# DCAN_0_DATA register map
Vendor: Texas Instruments
Peripheral module from a debugger description file (folder 66AK2G0x_66AK2G1x).
Registers are 32-bit, read-only, reset 0x0 unless marked. A register's access mark holds for its fields unless they carry their own. Offsets are as the file gives them; lines under a group give offsets from that group; [hi:lo] are bit positions; {n}, {i} and the like mark numbered series; 'fields as' and 'values as' point back to an identical list; <NAME> marks a mode.

## DCAN_0_DATA
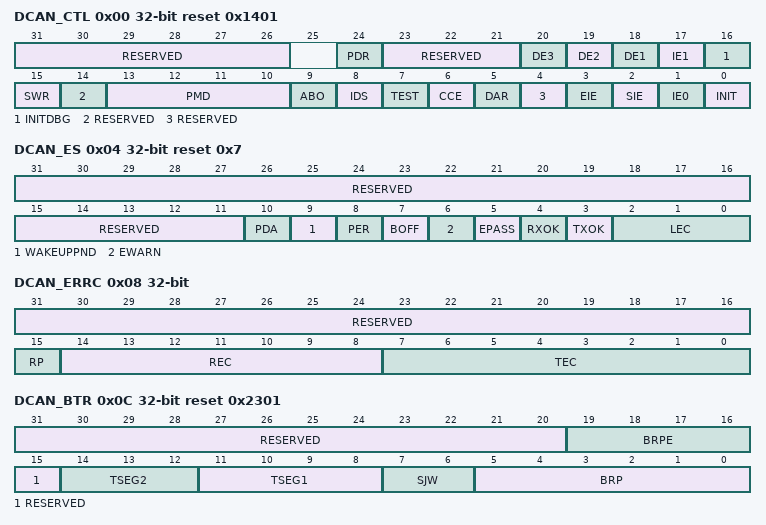
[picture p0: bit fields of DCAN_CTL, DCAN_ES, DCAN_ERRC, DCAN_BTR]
0x00 DCAN_CTL access per field reset 0x1401
  [31:26] RESERVED ro — These bits are always read as 0. Writes have no effect.
  [24] PDR rw — Request for local low power-down mode 0h (R/W) = No application request for local low power-down mode. If the application has cleared this bit while DCAN in local power-down mode, also the INIT bit has to be cleared. 1h (R/W) = Local power-down mode has been requested by application. The DCAN will acknowledge the local power-down mode by setting bit PDA in the
  [23:21] RESERVED ro — These bits are always read as 0. Writes have no effect.
  [20] DE3 rw — Enable DMA request line for IF3. Note: A pending DMA request for IF3 remains active until first access to one of the IF3 registers. 0h (R/W) = Disabled 1h (R/W) = Enabled
  [19] DE2 rw — Enable DMA request line for IF2. Note: A pending DMA request for IF2 remains active until first access to one of the IF2 registers. 0h (R/W) = Disabled 1h (R/W) = Enabled
  [18] DE1 rw — Enable DMA request line for IF1. Note: A pending DMA request for IF1 remains active until first access to one of the IF1 registers. 0h (R/W) = Disabled 1h (R/W) = Enabled
  [17] IE1 rw — Interrupt line 1 enable 0h (R/W) = Disabled - Module interrupt INT1 is always low. 1h (R/W) = Enabled - interrupts will assert line INT1 to one; line remains active until pending interrupts are processed.
  [16] INITDBG rw — Internal init state while debug access 0h (R/W) = Not in debug mode, or debug mode requested but not entered. 1h (R/W) = Debug mode requested and internally entered; the DCAN is ready for debug accesses.
  [15] SWR rw — Software reset enable. Note: To execute software reset, the following procedure is necessary: 0h (R/W) = Normal Operation 1h (R/W) = Module is forced to reset state. This bit will automatically get cleared after execution of software reset after one DCAN_i_VBUS_CLK (i = 0 or 1) clock cycle.
  [14] RESERVED ro — This bit is always read as 0. Writes have no effect.
  [13:10] PMD rw — ECC on/offOthers: function enabled. 5h (R/W) = function disabled
  [9] ABO rw — Auto-Bus-On enable 0h (R/W) = The Auto-Bus-On feature is disabled 1h (R/W) = The Auto-Bus-On feature is enabled
  [8] IDS rw — Interruption debug support enable 0h (R/W) = When Debug/Suspend mode is requested, DCAN will wait for a started transmission or reception to be completed before entering Debug/Suspend mode 1h (R/W) = When Debug/Suspend mode is requested, DCAN will interrupt any transmission or reception, and enter Debug/Suspend mode immediately.
  [7] TEST rw — Test mode enable 0h (R/W) = Normal Operation 1h (R/W) = Test Mode
  [6] CCE rw — Configuration change enable 0h (R/W) = The software has no write access to the configuration registers. 1h (R/W) = The software has write access to the configuration registers (when INIT bit is set).
  [5] DAR rw — Disable automatic retransmission 0h (R/W) = Automatic retransmission of not successful messages enabled. 1h (R/W) = Automatic retransmission disabled.
  [4] RESERVED ro — This bit is always read as 0. Writes have no effect.
  [3] EIE rw — Error interrupt enable 0h (R/W) = Disabled - PER, BOFF and EWARN bits can not generate an interrupt. 1h (R/W) = Enabled - PER, BOFF and EWARN bits can generate an interrupt at INT0 line and affect the interrupt register.
  [2] SIE rw — Status change interrupt enable 0h (R/W) = Disabled - WAKEUPPND, RXOK, TXOK and LEC bits can not generate an interrupt. 1h (R/W) = Enabled - WAKEUPPND, RXOK, TXOK and LEC can generate an interrupt at INT0 line and affect the interrupt register.
  [1] IE0 rw — Interrupt line 0 enable 0h (R/W) = Disabled - Module interrupt INT0 is always low. 1h (R/W) = Enabled - interrupts will assert line INT0 to one; line remains active until pending interrupts are processed.
  [0] INIT rw — Initialization 0h (R/W) = Normal operation 1h (R/W) = Initialization mode is entered
0x04 DCAN_ES access per field reset 0x7
  [31:11] RESERVED ro — These bits are always read as 0. Writes have no effect.
  [10] PDA ro — Local power-down mode acknowledge 0h (R) = DCAN is not in local power-down mode. 1h (R) = Application request for setting DCAN to local power-down mode was successful. DCAN is in local power-down mode.
  [9] WAKEUPPND ro — Wake up pending. This bit can be used by the software to identify the DCAN as the source to wake up the system. This bit will be reset if 0h (R) = No Wake Up is requested by DCAN. 1h (R) = DCAN has initiated a wake up of the system due to dominant CAN bus while module power down.
  [8] PER rw — Single/Double bit error detected. This bit will be set on double bit errors and additionally on single bit errors if single bit error correction is disabled with the ECCMODE bitfield in 0h (R/W) = No effect 1h (R/W) = End of interrupt (EOI) for single/double error on DCAN_ERR_INT interrupt line
  [7] BOFF ro — Bus-Off state 0h (R) = The CAN module is not bus-off state. 1h (R) = The CAN module is in bus-off state.
  [6] EWARN ro — Warning state 0h (R) = Both error counters are below the error warning limit of 96. 1h (R) = At least one of the error counters has reached the error warning limit of 96.
  [5] EPASS ro — Error passive state 0h (R) = On CAN Bus error, the DCAN could send active error frames. 1h (R) = The CAN core is in the error passive state as defined in the CAN Specification.
  [4] RXOK ro — Received a message successfully. This bit will be reset if 0h (R) = No message has been successfully received since the last time when this bit was read by the software. This bit is never reset by DCAN internal events. 1h (R) = A message has been successfully received since the last time when this bit was reset by a read access of the software (independent of the result of acceptance filtering).
  [3] TXOK ro — Transmitted a message successfully. This bit will be reset if 0h (R) = No message has been successfully transmitted since the last time when this bit was read by the software. This bit is never reset by DCAN internal events. 1h (R) = A message has been successfully transmitted (error free and acknowledged by at least one other node) since the last time when this bit was reset by a read access of the software.
  [2:0] LEC ro — Last error code. The LEC field indicates the type of the last error on the CAN bus. This field will be cleared to '0' when a message has been transferred (reception or transmission) without error. 0h (R) = No error 1h (R) = Stuff error: More than five equal bits in a row have been detected in a part of a received message where this is not allowed. 2h (R) = Form error: A fixed format part of a received frame has the wrong format. 3h (R) = Ack error: The message this CAN core transmitted was not acknowledged by another node. 4h (R) = Bit1 error: During the transmission of a message (with the exception of the arbitration field), the device wanted to send a recessive level (bit of logical value '1'), but the monitored bus value was dominant. 5h (R) = Bit0 error: During the transmission of a message (or acknowledge bit, or active error flag, or overload flag), the device wanted to send a dominant level (logical value '0'), but the monitored bus level was recessive. During Bus-Off recovery, this status is set each time a sequence of 11 recessive bits has been monitored. This enables the software to monitor the proceeding of the Bus-Off recovery sequence (indicating the bus is not stuck at dominant or continuously disturbed). 6h (R) = CRC error: In a received message, the CRC check sum was incorrect. (CRC received for an incoming message does not match the calculated CRC for the received data). 7h (R) = No CAN bus event was detected since the last time the software read
0x08 DCAN_ERRC
  [31:16] RESERVED — These bits are always read as 0. Writes have no effect.
  [15] RP — Receive error passive 0h (R) = The receive error counter is below the error passive level. 1h (R) = The receive error counter has reached the error passive level as defined in the CAN specification.
  [14:8] REC — Receive error counter. Actual state of the receive error counter
  [7:0] TEC — Transmit error counter. Actual state of the transmit error counter
0x0C DCAN_BTR access per field reset 0x2301
  [31:20] RESERVED ro — These bits are always read as 0. Writes have no effect.
  [19:16] BRPE rw — Baud rate prescaler extension.Valid programmed values are 0 to 15. By programming BRPE the baud rate prescaler can be extended to values up to 1024.
  [15] RESERVED ro — These bits are always read as 0. Writes have no effect.
  [14:12] TSEG2 rw — Time segment after the sample pointValid programmed values are 0 to 7. The actual TSeg2 value which is interpreted for the bit timing will be the programmed TSeg2 value + 1.
  [11:8] TSEG1 rw — Time segment before the sample pointValid programmed values are 1 to15. The actual TSeg1 value interpreted for the bit timing will be the programmed TSeg1 value + 1.
  [7:6] SJW rw — Synchronization Jump WidthValid programmed values are 0 to 3. The actual SJW value interpreted for the synchronization will be the programmed SJW value + 1.
  [5:0] BRP rw — Baud rate prescalerValue by which the CAN_CLK frequency is divided for generating the bit time quanta. The bit time is built up from a multiple of this quanta. Valid programmed values are 0 to 63. The actual BRP value interpreted for the bit timing will be the programmed BRP value + 1.
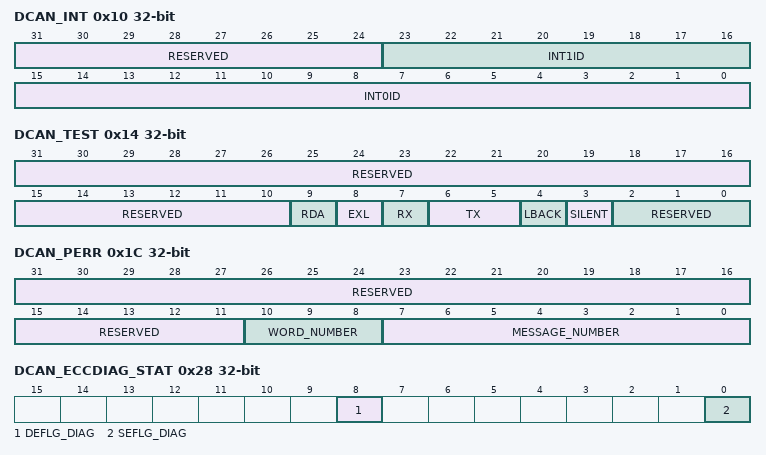
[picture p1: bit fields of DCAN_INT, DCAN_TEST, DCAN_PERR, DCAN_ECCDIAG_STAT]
0x10 DCAN_INT
  [31:24] RESERVED — These bits are always read as 0. Writes have no effect.
  [23:16] INT1ID — Interrupt 1 Identifier (indicates the message object with the highest pending interrupt)0x01-0x80: Number of message object which caused the interrupt. 0x81-0xFF: Unused. If several interrupts are pending, 0h (R) = No interrupt is pending
  [15:0] INT0ID — Interrupt Identifier (the number here indicates the source of the interrupt)0x0001-0x0080: Number of message object which caused the interrupt. 0x0081-0x7FFF: Unused. 0x8001-0xFFFF: Unused. If several interrupts are pending,DCAN_INTwill point to the pending interrupt with the highest priority. The INT0 interrupt line remains active until INT0ID reaches value 0 (the cause of the interrupt is reset) or until IE0 is cleared. The Status interrupt has the highest priority. Among the message interrupts, the message object's interrupt priority decreases with increasing message number. 0h (R) = No interrupt is pending 8000h (R) =
0x14 DCAN_TEST access per field (reset mask 0xFFFFFF7F)
  [31:10] RESERVED ro — These bits are always read as 0. Writes have no effect.
  [9] RDA rw — RAM direct access enable 0h (R/W) = Normal operation 1h (R/W) = Direct access to the RAM is enabled while in test mode
  [8] EXL rw — External loopback mode. When the internal loop-back mode is active (bit LBACK is set), bit EXL will be ignored. 0h (R/W) = Disabled 1h (R/W) = Enabled
  [7] RX ro — Receive pin. Monitors the actual value of the CAN_RX pin 0h (R) = The CAN bus is dominant 1h (R) = The CAN bus is recessive
  [6:5] TX rw — Control of CAN_TX pin. Setting Tx[1:0] other than '00' will disturb message transfer. 0h (R/W) = Normal operation, CAN_TX is controlled by the CAN core. 1h (R/W) = Sample point can be monitored at CAN_TX pin. 2h (R/W) = CAN_TX pin drives a dominant value. 3h (R/W) = CAN_TX pin drives a recessive value.
  [4] LBACK rw — Loopback mode. When the internal loop-back mode is active (bit LBACK is set), bit EXL will be ignored. 0h (R/W) = Disabled 1h (R/W) = Enabled
  [3] SILENT rw — Silent mode 0h (R/W) = Disabled 1h (R/W) = Enabled
  [2:0] RESERVED ro — These bits are always read as 0. Writes have no effect.
0x1C DCAN_PERR (reset mask 0xFFFFF800)
  [31:11] RESERVED — These bits are always read as 0. Writes have no effect.
  [10:8] WORD_NUMBER — Word number where parity error has been detectedRDA word number (1 to 5) of the message object (according to the message RAM representation in RDA mode).
  [7:0] MESSAGE_NUMBER — Message object number where parity error has been detected (0x01-0x80)
0x20 DCAN_REL reset 0xA3170504
  [31:0] REVISION — TI internal data. Identifies revision of peripheral.
0x24 DCAN_ECCDIAG access per field reset 0xA
  [3:0] ECCDIAG rw — SECDED diagnostic mode enable/disable
0x28 DCAN_ECCDIAG_STAT access per field
  [8] DEFLG_DIAG rw — Double bit error flag diagnostic
  [0] SEFLG_DIAG rw — Single bit error flag diagnostic
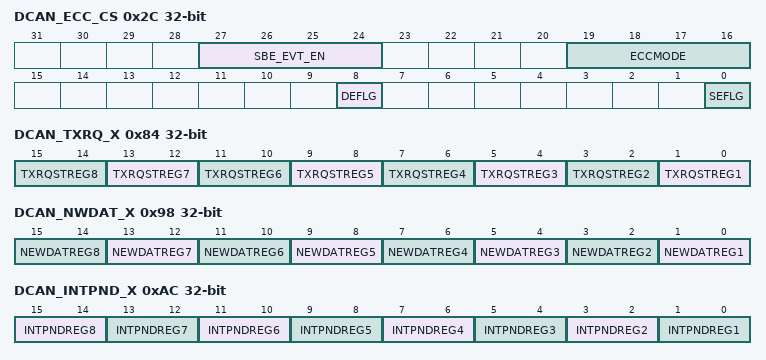
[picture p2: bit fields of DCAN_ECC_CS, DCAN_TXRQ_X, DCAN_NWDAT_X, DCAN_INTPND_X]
0x2C DCAN_ECC_CS access per field
  [27:24] SBE_EVT_EN rw — Enable/disable SECDED single bit error event (CAN_SERR signal). Write in privileged mode only.
  [19:16] ECCMODE rw — Enable/disable SECDED single bit error correction. Write in privileged mode only.
  [8] DEFLG rw — Double bit error flag
  [0] SEFLG rw — Single bit error flag
0x30 DCAN_ECC_SERR access per field (reset mask 0xFFFFFF00)
  [7:0] MESSAGE_NUMBER rw — Message object number where ECC single bit error has been detected. 0x0: Reserved
0x80 DCAN_ABOTR rw
  [31:0] ABO_TIME — Number of DCAN_i_VBUS_CLK (i = 0 or 1) clock cycles before a Bus-Off recovery sequence is started by clearing the INIT bit. This function has to be enabled by setting bit ABO in
0x84 DCAN_TXRQ_X
  [2n-1:2n-2] TXRQSTREG{n} (n=1..8) — Transmission request bits (aggregate for {16n-15}-{16n} message objects). Lower bit represents first 8 message objects. Higher bit represents second 8 message objects.
0x88 DCAN_TXRQ12
  [31:0] TXRQS — Transmission request bits (for 1-32 message objects)
0x8C DCAN_TXRQ34
  [31:0] TXRQS — Transmission request bits (for 33-64 message objects)
0x90 DCAN_TXRQ56
  [31:0] TXRQS — Transmission request bits (for 65-96 message objects)
0x94 DCAN_TXRQ78
  [31:0] TXRQS — Transmission request bits (for 97-128 message objects)
0x98 DCAN_NWDAT_X
  [2n-1:2n-2] NEWDATREG{n} (n=1..8) — New data bits (aggregate for {16n-15}-{16n} message objects). Lower bit represents first 8 message objects. Higher bit represents second 8 message objects.
0x9C DCAN_NWDAT12
  [31:0] NEWDAT — New Data Bits (for 1-32 message objects)
0xA0 DCAN_NWDAT34
  [31:0] NEWDAT — New Data Bits (for 33-64 message objects)
0xA4 DCAN_NWDAT56
  [31:0] NEWDAT — New Data Bits (for 65-96 message objects)
0xA8 DCAN_NWDAT78
  [31:0] NEWDAT — New Data Bits (for 97-128 message objects)
0xAC DCAN_INTPND_X
  [15:14] INTPNDREG8 — Interrupt Pending bits (aggregate for 113-128 message objects). Lower bit represents first 8 message objects. Higher bit represents second 8 message objects.
  [13:12] INTPNDREG7 — Interrupt Pending bits (aggregate for 97-112 message objects). Lower bit represents first 8 message objects. Higher bit represents second 8 message objects.
  [11:10] INTPNDREG6 — Interrupt Pendingbits (aggregate for 81-96 message objects). Lower bit represents first 8 message objects. Higher bit represents second 8 message objects.
  [2n-1:2n-2] INTPNDREG{n} (n=1..5) — Interrupt Pending bits (aggregate for {16n-15}-{16n} message objects). Lower bit represents first 8 message objects. Higher bit represents second 8 message objects.
0xB0 DCAN_INTPND12
  [31:0] INTPND — Interrupt Pending Bits (for 1-32 message objects) 0h (R) = This message object is not the source of an interrupt. 1h (R) = This message object is the source of an interrupt.
0xB4 DCAN_INTPND34
  [31:0] INTPND — Interrupt Pending Bits (for 33-64 message objects) 0h (R) = This message object is not the source of an interrupt. 1h (R) = This message object is the source of an interrupt.
0xB8 DCAN_INTPND56
  [31:0] INTPND — Interrupt Pending Bits (for 65-96 message objects) 0h (R) = This message object is not the source of an interrupt. 1h (R) = This message object is the source of an interrupt.
0xBC DCAN_INTPND78
  [31:0] INTPND — Interrupt Pending Bits (for 97-128 message objects) 0h (R) = This message object is not the source of an interrupt. 1h (R) = This message object is the source of an interrupt.
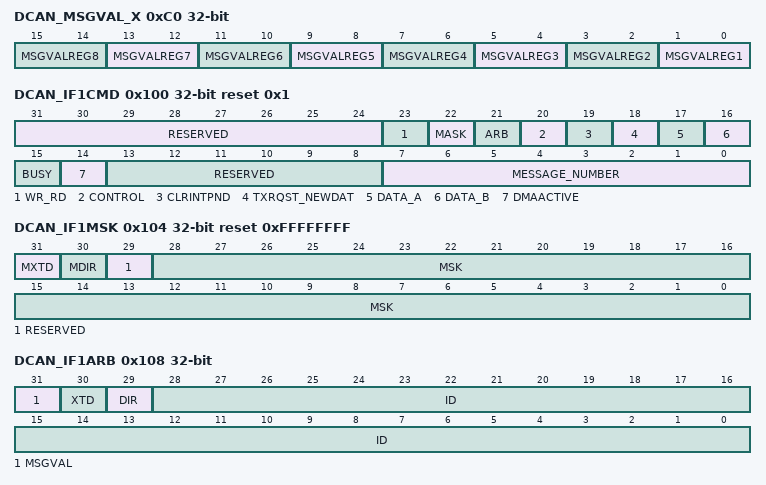
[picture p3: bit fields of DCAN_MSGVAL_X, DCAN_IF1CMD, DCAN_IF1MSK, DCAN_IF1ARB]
0xC0 DCAN_MSGVAL_X
  [2n-1:2n-2] MSGVALREG{n} (n=1..8) — Message valid bits (aggregate for {16n-15}-{16n} message objects). Lower bit represents first 8 message objects. Higher bit represents second 8 message objects.
0xC4 DCAN_MSGVAL12
  [31:0] MSGVAL — Message valid Bits (for 1-32 message objects) 0h (R) = This message object is ignored by the message handler. 1h (R) = This message object is configured and will be considered by the message handler.
0xC8 DCAN_MSGVAL34
  [31:0] MSGVAL — Message valid Bits (for 33-64 message objects) 0h (R) = This message object is ignored by the message handler. 1h (R) = This message object is configured and will be considered by the message handler.
0xCC DCAN_MSGVAL56
  [31:0] MSGVAL — Message valid Bits (for 65-96 message objects) 0h (R) = This message object is ignored by the message handler. 1h (R) = This message object is configured and will be considered by the message handler.
0xD0 DCAN_MSGVAL78
  [31:0] MSGVAL — Message valid Bits (for 97-128 message objects) 0h (R) = This message object is ignored by the message handler. 1h (R) = This message object is configured and will be considered by the message handler.
0xD8 DCAN_INTMUX12 rw
  [31:0] INTMUX — Multiplexes IntPnd value to either INT0 or INT1 interrupt lines (bit 0 -&gt; last implemented message object) ( bits 1:31 -&gt; 1-31 message objects) 0h (R/W) = INT0 line is active if corresponding IntPnd flag is one. 1h (R/W) = INT1 line is active if corresponding IntPnd flag is one.
0xDC DCAN_INTMUX34 rw
  [31:0] INTMUX — Multiplexes IntPnd value to either INT0 or INT1 interrupt lines ( bits 0:31 -&gt; 32-63 message objects) 0h (R/W) = INT0 line is active if corresponding IntPnd flag is one. 1h (R/W) = INT1 line is active if corresponding IntPnd flag is one.
0xE0 DCAN_INTMUX56 rw
  [31:0] INTMUX — Multiplexes IntPnd value to either INT0 or INT1 interrupt lines ( bits 0:31 -&gt; 64-95 message objects) 0h (R/W) = INT0 line is active if corresponding IntPnd flag is one. 1h (R/W) = INT1 line is active if corresponding IntPnd flag is one.
0xE4 DCAN_INTMUX78 rw
  [31:0] INTMUX — Multiplexes IntPnd value to either INT0 or INT1 interrupt lines ( bits 0:31 -&gt; 96-127 message objects) 0h (R/W) = INT0 line is active if corresponding IntPnd flag is one. 1h (R/W) = INT1 line is active if corresponding IntPnd flag is one.
0x100 DCAN_IF1CMD access per field reset 0x1
  [31:24] RESERVED ro — These bits are always read as 0. Writes have no effect.
  [23] WR_RD rw — Write/Read 0h (R/W) = Direction = Read: Transfer direction is from the message object addressed by MESSAGE_NUMBER to the IF1 register set. 1h (R/W) = Direction = Write: Transfer direction is from the IF1 register set to the message object addressed by MESSAGE_NUMBER.
  [22] MASK rw — Access mask bits 0h (R/W) = Mask bits will not be changed 1h (R/W) = Direction = Write: The mask bits (identifier mask + MDir + MXtd) will be transferred from the IF1 register set to the message object addressed by MESSAGE_NUMBER.
  [21] ARB rw — Access arbitration bits 0h (R/W) = Arbitration bits will not be changed 1h (R/W) = Direction = Write: The Arbitration bits (Identifier + Dir + Xtd + MsgVal) will be transferred from the IF1 register set to the message object addressed by MESSAGE_NUMBER.
  [20] CONTROL rw — Access control bitsIf the TXRQST_NEWDAT bit in this register(Bit [18]) is set, the TXRQST/ NEWDAT bits in the 0h (R/W) = Control bits will not be changed 1h (R/W) = Direction = Write: The message control bits will be transferred from the IF1 registerset to the message object addressed by MESSAGE_NUMBER.
  [19] CLRINTPND rw — Clear interrupt pending bit 0h (R/W) = IntPnd bit will not be changed 1h (R/W) = Direction = Write: This bit is ignored. Copying of IntPnd flag from IF1 Registers to message RAM can only be controlled by the CONTROL flag (Bit [20]).
  [18] TXRQST_NEWDAT rw — Access transmission request bitNote: If a CAN transmission is requested by setting TXRQST_NEWDAT in this register, the TxRqst/NewDat bits in the message object will be set to one independent of the values in 0h (R/W) = Direction = Read: NewDat bit will not be changed. Direction = Write: TxRqst/NewDat bit will be handled according to the CONTROL bit. 1h (R/W) = Direction = Read: Clears NewDat bit in the message object. 1: Direction = Write: Sets TxRqst/NewDat in message object.
  [17] DATA_A rw — Access Data Bytes 0-3Note: The duration of the message transfer is independent of the number of bytes to be transferred. 0h (R/W) = Data Bytes 0-3 will not be changed. 1h (R/W) = Direction = Write: The data bytes 0-3 will be transferred from the IF1 registerset to the message object addressed by the MESSAGE_NUMBER.
  [16] DATA_B rw — Access Data Bytes 4-7Note: The duration of the message transfer is independent of the number of bytes to be transferred. 0h (R/W) = Data Bytes 4-7 will not be changed. 1h (R/W) = Direction = Write: The data bytes 4-7 will be transferred from the IF1 registerset to the message object addressed by MESSAGE_NUMBER.
  [15] BUSY rw — Busy flagThis bit is set to one after the message number has been written to bits [7-0] MESSAGE_NUMBER. IF1 register set will be write protected. The bit is cleared after read/write action has been finished. 0h (R/W) = No transfer between IF1 register set and message RAM is in progress. 1h (R/W) = Transfer between IF1 register set and message RAM is in progress.
  [14] DMAACTIVE rw — Activation of DMA feature for subsequent internal IF1 updateThe DMA request remains active until the first read or write to one of the IF1 registers; an exception is a write to MESSAGE_NUMBER when DMAACTIVE is one. Note: Due to the auto reset feature of the DMAACTIVE bit, this bit has to be set for each subsequent DMA cycle separately. 0h (R/W) = DMA request line is independent of IF1 activities. 1h (R/W) = DMA is requested after completed transfer between IF1 register set and message RAM.
  [13:8] RESERVED ro — These bits are always read as 0. Writes have no effect.
  [7:0] MESSAGE_NUMBER rw — Number of message object in message RAM which is used for data transfer0x01-0x80: Valid message numbers. 0x81-0xFF: Invalid message numbers. 0h (R/W) = Invalid message number
0x104 DCAN_IF1MSK access per field reset 0xFFFFFFFF
  [31] MXTD rw — Mask Extended IdentifierWhen 11-bit ( standard ) identifiers are used for a message object, the identifiers of received data frames are written into bits ID[28-18]. For acceptance filtering, only these bits together with mask bits Msk[28-18] are considered. 0h (R/W) = The extended identifier bit (IDE) has no effect on the acceptance filtering. 1h (R/W) = The extended identifier bit (IDE) is used for acceptance filtering.
  [30] MDIR rw — Mask Message Direction 0h (R/W) = The message direction bit (Dir) has no effect on the acceptance filtering. 1h (R/W) = The message direction bit (Dir) is used for acceptance filtering.
  [29] RESERVED ro — This bit is always read as 1. Writes have no effect.
  [28:0] MSK rw — Identifier Mask 0h (R/W) = The corresponding bit in the identifier of the message object is not used for acceptance filtering (don't care). 1h (R/W) = The corresponding bit in the identifier of the message object is used for acceptance filtering.
0x108 DCAN_IF1ARB rw
  [31] MSGVAL — Message validThe software should reset the MsgVal bit of all unused Messages Objects during the initialization before it resets bit INIT in the 0h (R/W) = The message object is ignored by the message handler. 1h (R/W) = The message object is to be used by the message handler.
  [30] XTD — Extended identifier 0h (R/W) = The 11-bit (standard) Identifier is used for this message object. 1h (R/W) = The 29-bit (extended) Identifier is used for this message object.
  [29] DIR — Message direction 0h (R/W) = Direction = receive: On TxRqst, a remote frame with the identifier of this message object is transmitted. On reception of a data frame with matching identifier, this message is stored in this message object. 1h (R/W) = Direction = transmit: On TxRqst, the respective message object is transmitted as a data frame. On reception of a remote frame with matching identifier, the TxRqst bit of this message object is set (if RmtEn = 1).
  [28:0] ID — Message identifierID[28-0]: 29-bit identifier (extended frame). ID[28-18]: 11-bit identifier (standard frame).
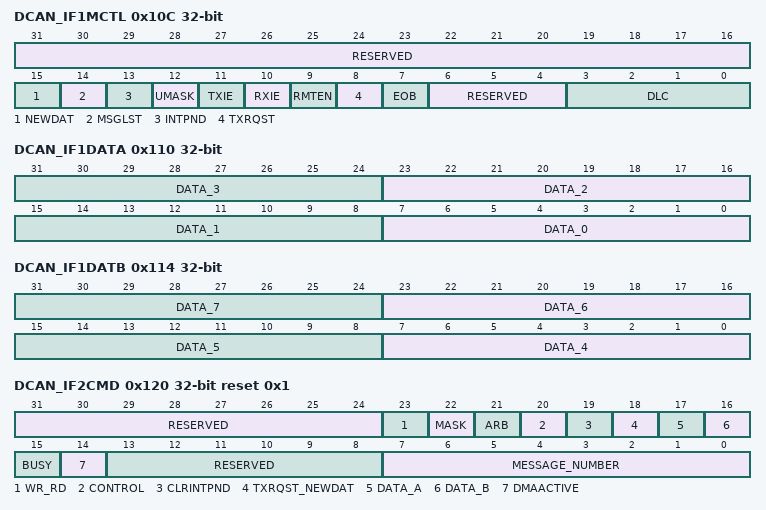
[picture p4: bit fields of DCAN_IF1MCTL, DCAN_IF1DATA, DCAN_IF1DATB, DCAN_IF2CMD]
0x10C DCAN_IF1MCTL access per field
  [31:16] RESERVED ro — These bits are always read as 0. Writes have no effect.
  [15] NEWDAT rw — New data 0h (R/W) = No new data has been written into the data portion of this message object by the message handler since the last time when this flag was cleared by the software. 1h (R/W) = The message handler or the software has written new data into the data portion of this message object.
  [14] MSGLST rw — Message lost (only valid for message objects with direction = receive) 0h (R/W) = No message lost since the last time when this bit was reset by the software. 1h (R/W) = The message handler stored a new message into this object when NewDat was still set, so the previous message has been overwritten.
  [13] INTPND rw — Interrupt pending 0h (R/W) = This message object is not the source of an interrupt. 1h (R/W) = This message object is the source of an interrupt. The Interrupt Identifier in
  [12] UMASK rw — Use acceptance maskIf the UMASK bit is set to one, the message object's mask bits have to be programmed during initialization of the message object before MsgVal is set to one. 0h (R/W) = Mask ignored 1h (R/W) = Use mask (Msk[28-0], MXtd, and MDir) for acceptance filtering
  [11] TXIE rw — Transmit interrupt enable 0h (R/W) = IntPnd will not be triggered after the successful transmission of a frame. 1h (R/W) = IntPnd will be triggered after the successful transmission of a frame.
  [10] RXIE rw — Receive interrupt enable 0h (R/W) = IntPnd will not be triggered after the successful reception of a frame. 1h (R/W) = IntPnd will be triggered after the successful reception of a frame.
  [9] RMTEN rw — Remote enable 0h (R/W) = At the reception of a remote frame, TxRqst is not changed. 1h (R/W) = At the reception of a remote frame, TxRqst is set.
  [8] TXRQST rw — Transmit request 0h (R/W) = This message object is not waiting for a transmission. 1h (R/W) = The transmission of this message object is requested and is not yet done.
  [7] EOB rw — End of BlockNote: This bit is used to concatenate multiple message objects to build a FIFO Buffer. For single message objects (not belonging to a FIFO Buffer), this bit must always be set to 1. 0h (R/W) = The message object is part of a FIFO Buffer block and is not the last message object of the FIFO Buffer block. 1h (R/W) = The message object is a single message object or the last message object in a FIFO Buffer Block.
  [6:4] RESERVED ro — These bits are always read as 0. Writes have no effect.
  [3:0] DLC rw — Data length code0-8: Data frame has 0-8 data bytes. 9-15 Data frame has 8 data bytes. Note: The data length code of a message object must be defined the same as in all the corresponding objects with the same identifier at other nodes. When the message handler stores a data frame, it will write the DLC to the value given by the received message.
0x110 DCAN_IF1DATA rw
  [8n+7:8n] DATA_{n} (n=0..3) — Data byte {n}
0x114 DCAN_IF1DATB rw
  [8n-25:8n-32] DATA_{n} (n=4..7) — Data byte {n}
0x120 DCAN_IF2CMD access per field reset 0x1
  [31:24] RESERVED ro — These bits are always read as 0. Writes have no effect.
  [23] WR_RD rw — Write/Read 0h (R/W) = Direction = Read: Transfer direction is from the message object addressed by MESSAGE_NUMBER to the IF2 register set. 1h (R/W) = Direction = Write: Transfer direction is from the IF2 register set to the message object addressed by MESSAGE_NUMBER.
  [22] MASK rw — Access mask bits 0h (R/W) = Mask bits will not be changed 1h (R/W) = Direction = Write: The mask bits (identifier mask + MDir + MXtd) will be transferred from the IF2 register set to the message object addressed by MESSAGE_NUMBER.
  [21] ARB rw — Access arbitration bits 0h (R/W) = Arbitration bits will not be changed 1h (R/W) = Direction = Write: The Arbitration bits (Identifier + Dir + Xtd + MsgVal) will be transferred from the IF2 register set to the message object addressed by MESSAGE_NUMBER.
  [20] CONTROL rw — Access control bitsIf the TXRQST_NEWDAT bit in this register(Bit [18]) is set, the TXRQST/ NEWDAT bits in the 0h (R/W) = Control bits will not be changed 1h (R/W) = Direction = Write: The message control bits will be transferred from the IF2 registerset to the message object addressed by MESSAGE_NUMBER.
  [19] CLRINTPND rw — Clear interrupt pending bit 0h (R/W) = IntPnd bit will not be changed 1h (R/W) = Direction = Write: This bit is ignored. Copying of IntPnd flag from IF2 Registers to message RAM can only be controlled by the CONTROL flag (Bit [20]).
  [18] TXRQST_NEWDAT rw — Access transmission request bitNote: If a CAN transmission is requested by setting TXRQST_NEWDAT in this register, the TxRqst/NewDat bits in the message object will be set to one independent of the values in 0h (R/W) = Direction = Read: NewDat bit will not be changed. Direction = Write: TxRqst/NewDat bit will be handled according to the CONTROL bit. 1h (R/W) = Direction = Read: Clears NewDat bit in the message object. 1: Direction = Write: Sets TxRqst/NewDat in message object.
  [17] DATA_A rw — Access Data Bytes 0-3Note: The duration of the message transfer is independent of the number of bytes to be transferred. 0h (R/W) = Data Bytes 0-3 will not be changed. 1h (R/W) = Direction = Write: The data bytes 0-3 will be transferred from the IF2 registerset to the message object addressed by the MESSAGE_NUMBER.
  [16] DATA_B rw — Access Data Bytes 4-7Note: The duration of the message transfer is independent of the number of bytes to be transferred. 0h (R/W) = Data Bytes 4-7 will not be changed. 1h (R/W) = Direction = Write: The data bytes 4-7 will be transferred from the IF2 registerset to the message object addressed by MESSAGE_NUMBER.
  [15] BUSY rw — Busy flagThis bit is set to one after the message number has been written to bits [7-0] MESSAGE_NUMBER. IF2 register set will be write protected. The bit is cleared after read/write action has been finished. 0h (R/W) = No transfer between IF2 register set and message RAM is in progress. 1h (R/W) = Transfer between IF2 register set and message RAM is in progress.
  [14] DMAACTIVE rw — Activation of DMA feature for subsequent internal IF2 update The DMA request remains active until the first read or write to one of the IF2 registers; an exception is a write to MESSAGE_NUMBER when DMAACTIVE is one. Note: Due to the auto reset feature of the DMAACTIVE bit, this bit has to be set for each subsequent DMA cycle separately. 0h (R/W) = DMA request line is independent of IF2 activities. 1h (R/W) = DMA is requested after completed transfer between IF2 register set and message RAM.
  [13:8] RESERVED ro — These bits are always read as 0. Writes have no effect.
  [7:0] MESSAGE_NUMBER rw — Number of message object in message RAM which is used for data transfer0x01-0x80: Valid message numbers. 0x81-0xFF: Invalid message numbers. 0h (R/W) = Invalid message number
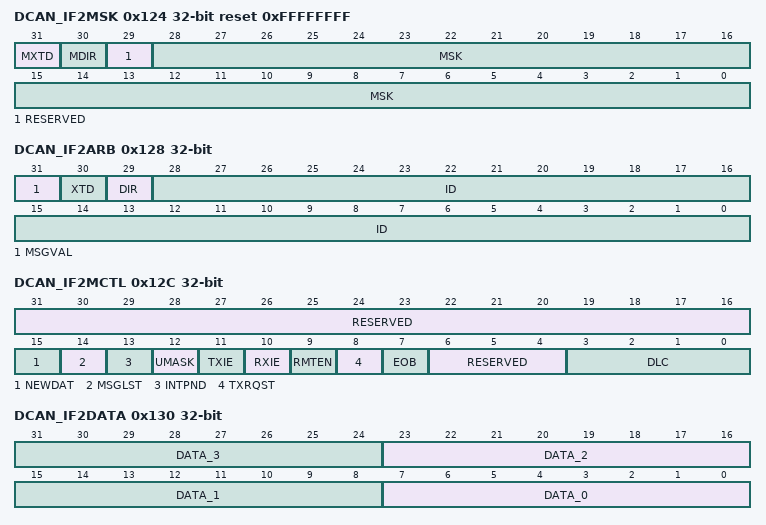
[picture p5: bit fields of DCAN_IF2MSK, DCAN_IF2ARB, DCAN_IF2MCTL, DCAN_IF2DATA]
0x124 DCAN_IF2MSK access per field reset 0xFFFFFFFF
  [31] MXTD rw — Mask Extended IdentifierWhen 11-bit (standard) identifiers are used for a message object, the identifiers of received data frames are written into bits ID[28-18]. For acceptance filtering, only these bits together with mask bits Msk[28-18] are considered. 0h (R/W) = The extended identifier bit (IDE) has no effect on the acceptance filtering. 1h (R/W) = The extended identifier bit (IDE) is used for acceptance filtering.
  [30] MDIR rw — Mask Message Direction 0h (R/W) = The message direction bit (Dir) has no effect on the acceptance filtering. 1h (R/W) = The message direction bit (Dir) is used for acceptance filtering.
  [29] RESERVED ro — This bit is always read as 1. Writes have no effect.
  [28:0] MSK rw — Identifier Mask 0h (R/W) = The corresponding bit in the identifier of the message object is not used for acceptance filtering (don't care). 1h (R/W) = The corresponding bit in the identifier of the message object is used for acceptance filtering.
0x128 DCAN_IF2ARB rw
  fields as DCAN_IF1ARB
0x12C DCAN_IF2MCTL access per field
  [31:16] RESERVED ro — These bits are always read as 0. Writes have no effect.
  [15] NEWDAT rw — New data 0h (R/W) = No new data has been written into the data portion of this message object by the message handler since the last time when this flag was cleared by the software. 1h (R/W) = The message handler or the software has written new data into the data portion of this message object.
  [14] MSGLST rw — Message lost (only valid for message objects with direction = receive) 0h (R/W) = No message lost since the last time when this bit was reset by the software. 1h (R/W) = The message handler stored a new message into this object when NewDat was still set, so the previous message has been overwritten.
  [13] INTPND rw — Interrupt pending 0h (R/W) = This message object is not the source of an interrupt. 1h (R/W) = This message object is the source of an interrupt. The Interrupt Identifier in
  [12] UMASK rw — Use acceptance maskIf the UMask bit is set to one, the message object's mask bits have to be programmed during initialization of the message object before MsgVal is set to one. 0h (R/W) = Mask ignored 1h (R/W) = Use mask (Msk[28-0], MXtd, and MDir) for acceptance filtering
  [11] TXIE rw — Transmit interrupt enable 0h (R/W) = IntPnd will not be triggered after the successful transmission of a frame. 1h (R/W) = IntPnd will be triggered after the successful transmission of a frame.
  [10] RXIE rw — Receive interrupt enable 0h (R/W) = IntPnd will not be triggered after the successful reception of a frame. 1h (R/W) = IntPnd will be triggered after the successful reception of a frame.
  [9] RMTEN rw — Remote enable 0h (R/W) = At the reception of a remote frame, TxRqst is not changed. 1h (R/W) = At the reception of a remote frame, TxRqst is set.
  [8] TXRQST rw — Transmit request 0h (R/W) = This message object is not waiting for a transmission. 1h (R/W) = The transmission of this message object is requested and is not yet done.
  [7] EOB rw — End of BlockNote: This bit is used to concatenate multiple message objects to build a FIFO Buffer. For single message objects (not belonging to a FIFO Buffer), this bit must always be set to one. 0h (R/W) = The message object is part of a FIFO Buffer block and is not the last message object of the FIFO Buffer block. 1h (R/W) = The message object is a single message object or the last message object in a FIFO Buffer Block.
  [6:4] RESERVED ro — These bits are always read as 0. Writes have no effect.
  [3:0] DLC rw — Data length code0-8: Data frame has 0-8 data bytes. 9-15 Data frame has 8 data bytes. Note: The data length code of a message object must be defined the same as in all the corresponding objects with the same identifier at other nodes. When the message handler stores a data frame, it will write the DLC to the value given by the received message.
0x130 DCAN_IF2DATA rw
  [8n+7:8n] DATA_{n} (n=0..3) — Data byte {n}
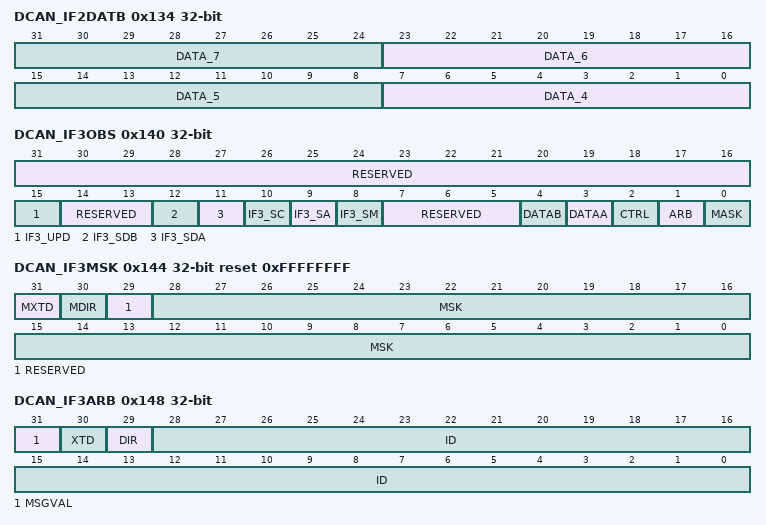
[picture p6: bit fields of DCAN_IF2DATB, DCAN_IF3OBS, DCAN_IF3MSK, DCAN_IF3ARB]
0x134 DCAN_IF2DATB rw
  [8n-25:8n-32] DATA_{n} (n=4..7) — Data byte {n}
0x140 DCAN_IF3OBS access per field
  [31:16] RESERVED ro — These bits are always read as 0. Writes have no effect.
  [15] IF3_UPD ro — IF3 Update Data 0h (R) = No new data has been loaded since last IF3 read. 1h (R) = New data has been loaded since last IF3 read.
  [14:13] RESERVED ro — These bits are always read as 0. Writes have no effect.
  [12] IF3_SDB ro — IF3 Status of Data B read access 0h (R) = All Data B bytes are already read out, or are not marked to be read. 1h (R) = Data B section has still data to be read out.
  [11] IF3_SDA ro — IF3 Status of Data A read access 0h (R) = All Data A bytes are already read out, or are not marked to be read. 1h (R) = Data A section has still data to be read out.
  [10] IF3_SC ro — IF3 Status of control bits read access 0h (R) = All control section bytes are already read out, or are not marked to be read. 1h (R) = Control section has still data to be read out.
  [9] IF3_SA ro — IF3 Status of Arbitration data read access 0h (R) = All Arbitration data bytes are already read out, or are not marked to be read. 1h (R) = Arbitration section has still data to be read out.
  [8] IF3_SM ro — IF3 Status of Mask data read access 0h (R) = All mask data bytes are already read out, or are not marked to be read. 1h (R) = Mask section has still data to be read out.
  [7:5] RESERVED ro — These bits are always read as 0. Writes have no effect.
  [4] DATAB rw — Data B read observation 0h (R/W) = Data B section has not to be read. 1h (R/W) = Data B section has to be read to enable next IF3 update.
  [3] DATAA rw — Data A read observation 0h (R/W) = Data A section has not to be read. 1h (R/W) = Data A section has to be read to enable next IF3 update.
  [2] CTRL rw — Ctrl read observation 0h (R/W) = Ctrl section has not to be read. 1h (R/W) = Ctrl section has to be read to enable next IF3 update.
  [1] ARB rw — Arbitration data read observation 0h (R/W) = Arbitration data has not to be read. 1h (R/W) = Arbitration data has to be read to enable next IF3 update.
  [0] MASK rw — Mask data read observation 0h (R/W) = Mask data has not to be read. 1h (R/W) = Mask data has to be read to enable next IF3 update.
0x144 DCAN_IF3MSK access per field reset 0xFFFFFFFF
  [31] MXTD ro — Mask Extended IdentifierWhen 11-bit ( standard ) identifiers are used for a message object, the identifiers of received data frames are written into bits ID[28-18]. For acceptance filtering, only these bits together with mask bits Msk[28-18] are considered. 0h (R) = The extended identifier bit (IDE) has no effect on the acceptance filtering. 1h (R) = The extended identifier bit (IDE) is used for acceptance filtering.
  [30] MDIR ro — Mask Message Direction 0h (R) = The message direction bit (Dir) has no effect on the acceptance filtering. 1h (R) = The message direction bit (Dir) is used for acceptance filtering.
  [29] RESERVED ro — These bits are always read as 1. Writes have no effect.
  [28:0] MSK rw — Identifier Mask 0h (R/W) = The corresponding bit in the identifier of the message object is not used for acceptance filtering (don't care). 1h (R/W) = The corresponding bit in the identifier of the message object is used for acceptance filtering.
0x148 DCAN_IF3ARB
  [31] MSGVAL — Message ValidThe software should reset the MsgVal bit of all unused Messages Objects during the initialization before it resets bit INIT in the 0h (R) = The message object is ignored by the message handler. 1h (R) = The message object is to be used by the message handler.
  [30] XTD — Extended Identifier 0h (R) = The 11-bit (standard) Identifier is used for this message object. 1h (R) = The 29-bit (extended) Identifier is used for this message object.
  [29] DIR — Message Direction 0h (R) = Direction = receive: On TxRqst, a remote frame with the identifier of this message object is transmitted. On reception of a data frame with matching identifier, this message is stored in this message object. 1h (R) = Direction = transmit: On TxRqst, the respective message object is transmitted as a data frame. On reception of a remote frame with matching identifier, the TxRqst bit of this message object is set (if RmtEn = 1).
  [28:0] ID — Message IdentifierID[28-0]: 29-bit Identifier (extended frame). ID[28-18]: 11-bit Identifier (standard frame).
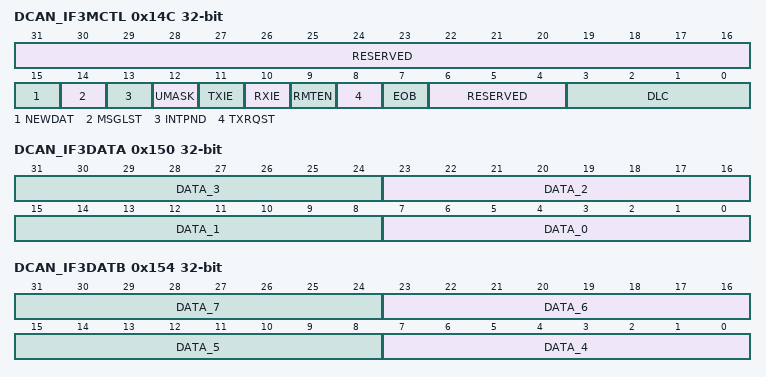
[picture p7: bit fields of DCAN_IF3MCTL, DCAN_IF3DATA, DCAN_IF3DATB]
0x14C DCAN_IF3MCTL
  [31:16] RESERVED — These bits are always read as 0. Writes have no effect.
  [15] NEWDAT — New Data 0h (R) = No new data has been written into the data portion of this message object by the message handler since the last time when this flag was cleared by the software. 1h (R) = The message handler or the software has written new data into the data portion of this message object.
  [14] MSGLST — Message Lost (only valid for message objects with direction = receive) 0h (R) = No message lost since the last time when this bit was reset by the software. 1h (R) = The message handler stored a new message into this object when NewDat was still set, so the previous message has been overwritten.
  [13] INTPND — Interrupt Pending 0h (R) = This message object is not the source of an interrupt. 1h (R) = This message object is the source of an interrupt. The Interrupt Identifier in
  [12] UMASK — Use Acceptance MaskIf the UMASK bit is set to one, the message object's mask bits have to be programmed during initialization of the message object before MsgVal is set to one. 0h (R) = Mask ignored 1h (R) = Use mask (Msk[28-0], MXtd, and MDir) for acceptance filtering
  [11] TXIE — Transmit Interrupt enable 0h (R) = IntPnd will not be triggered after the successful transmission of a frame. 1h (R) = IntPnd will be triggered after the successful transmission of a frame.
  [10] RXIE — Receive Interrupt enable 0h (R) = IntPnd will not be triggered after the successful reception of a frame. 1h (R) = IntPnd will be triggered after the successful reception of a frame.
  [9] RMTEN — Remote enable 0h (R) = At the reception of a remote frame, TxRqst is not changed. 1h (R) = At the reception of a remote frame, TxRqst is set.
  [8] TXRQST — Transmit Request 0h (R) = This message object is not waiting for a transmission. 1h (R) = The transmission of this message object is requested and is not yet done.
  [7] EOB — End of BlockNote: This bit is used to concatenate multiple message objects to build a FIFO Buffer. For single message objects (not belonging to a FIFO Buffer), this bit must always be set to one. 0h (R) = The message object is part of a FIFO Buffer block and is not the last message object of the FIFO Buffer block. 1h (R) = The message object is a single message object or the last message object in a FIFO Buffer Block.
  [6:4] RESERVED — These bits are always read as 0. Writes have no effect.
  [3:0] DLC — Data Length Code0-8: Data frame has 0-8 data bits. 9-15: Data frame has 8 data bytes. Note: The data length code of a message object must be defined the same as in all the corresponding objects with the same identifier at other nodes. When the message handler stores a data frame, it will write the DLC to the value given by the received message.
0x150 DCAN_IF3DATA
  [8n+7:8n] DATA_{n} (n=0..3) — Data byte {n}
0x154 DCAN_IF3DATB
  [8n-25:8n-32] DATA_{n} (n=4..7) — Data byte {n}
0x160 DCAN_IF3UPD12 rw
  [31:0] IF3UPDEN — IF3 Update Enabled (for 1-32 message objects) 0h (R/W) = Automatic IF3 update is disabled for this message object. 1h (R/W) = Automatic IF3 update is enabled for this message object. A message object is scheduled to be copied to IF3 register set, if NewDat flag of the message object is active.
0x164 DCAN_IF3UPD34 rw
  [31:0] IF3UPDEN — IF3 Update Enabled (for 33-64 message objects) 0h (R/W) = Automatic IF3 update is disabled for this message object. 1h (R/W) = Automatic IF3 update is enabled for this message object. A message object is scheduled to be copied to IF3 register set, if NewDat flag of the message object is active.
0x168 DCAN_IF3UPD56 rw
  [31:0] IF3UPDEN — IF3 Update Enabled (for 65-96 message objects) 0h (R/W) = Automatic IF3 update is disabled for this message object. 1h (R/W) = Automatic IF3 update is enabled for this message object. A message object is scheduled to be copied to IF3 register set, if NewDat flag of the message object is active.
0x16C DCAN_IF3UPD78 rw
  [31:0] IF3UPDEN — IF3 Update Enabled (for 97-128 message objects) 0h (R/W) = Automatic IF3 update is disabled for this message object. 1h (R/W) = Automatic IF3 update is enabled for this message object. A message object is scheduled to be copied to IF3 register set, if NewDat flag of the message object is active.
